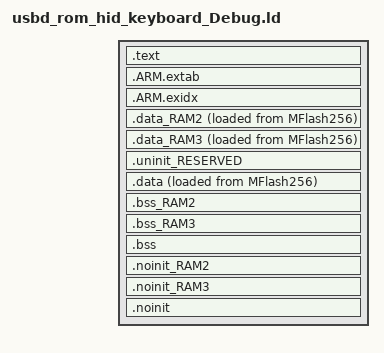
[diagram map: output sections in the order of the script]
/*
 * GENERATED FILE - DO NOT EDIT
 * Copyright 2008-2013 Code Red Technologies Ltd,
 * Copyright 2013-2025 NXP
 * SPDX-License-Identifier: BSD-3-Clause
 * Generated linker script file for LPC1549
 * Created from linkscript.ldt by FMCreateLinkLibraries
 * Using Freemarker v2.3.30
 * MCUXpresso IDE v25.6 [Build 136] [2025-06-27] on 17. 11. 2025 21:48:40
 */

INCLUDE "usbd_rom_hid_keyboard_Debug_library.ld"
INCLUDE "usbd_rom_hid_keyboard_Debug_memory.ld"

ENTRY(ResetISR)

SECTIONS
{
     /* MAIN TEXT SECTION */
    .text : ALIGN(4)
    {
        FILL(0xff)
        __vectors_start__ = ABSOLUTE(.) ;
        KEEP(*(.isr_vector))
        /* Global Section Table */
        . = ALIGN(4) ;
        __section_table_start = .;
        __data_section_table = .;
        LONG(LOADADDR(.data));
        LONG(    ADDR(.data));
        LONG(  SIZEOF(.data));
        LONG(LOADADDR(.data_RAM2));
        LONG(    ADDR(.data_RAM2));
        LONG(  SIZEOF(.data_RAM2));
        LONG(LOADADDR(.data_RAM3));
        LONG(    ADDR(.data_RAM3));
        LONG(  SIZEOF(.data_RAM3));
        __data_section_table_end = .;
        __bss_section_table = .;
        LONG(    ADDR(.bss));
        LONG(  SIZEOF(.bss));
        LONG(    ADDR(.bss_RAM2));
        LONG(  SIZEOF(.bss_RAM2));
        LONG(    ADDR(.bss_RAM3));
        LONG(  SIZEOF(.bss_RAM3));
        __bss_section_table_end = .;
        __section_table_end = . ;
        /* End of Global Section Table */

        *(.after_vectors*)

       *(.text*)
       *(.rodata .rodata.* .constdata .constdata.*)
       . = ALIGN(4);
    } > MFlash256
    /*
     * for exception handling/unwind - some Newlib functions (in common
     * with C++ and STDC++) use this.
     */
    .ARM.extab : ALIGN(4)
    {
        *(.ARM.extab* .gnu.linkonce.armextab.*)
    } > MFlash256

    .ARM.exidx : ALIGN(4)
    {
        __exidx_start = .;
        *(.ARM.exidx* .gnu.linkonce.armexidx.*)
        __exidx_end = .;
    } > MFlash256
 
    _etext = .;
        
    /* DATA section for Ram1_16 */

    .data_RAM2 : ALIGN(4)
    {
        FILL(0xff)
        PROVIDE(__start_data_RAM2 = .) ;
        PROVIDE(__start_data_Ram1_16 = .) ;
        *(.ramfunc.$RAM2)
        *(.ramfunc.$Ram1_16)
        *(.data.$RAM2)
        *(.data.$Ram1_16)
        *(.data.$RAM2.*)
        *(.data.$Ram1_16.*)
        . = ALIGN(4) ;
        PROVIDE(__end_data_RAM2 = .) ;
        PROVIDE(__end_data_Ram1_16 = .) ;
     } > Ram1_16 AT>MFlash256

    /* DATA section for Ram2_4 */

    .data_RAM3 : ALIGN(4)
    {
        FILL(0xff)
        PROVIDE(__start_data_RAM3 = .) ;
        PROVIDE(__start_data_Ram2_4 = .) ;
        *(.ramfunc.$RAM3)
        *(.ramfunc.$Ram2_4)
        *(.data.$RAM3)
        *(.data.$Ram2_4)
        *(.data.$RAM3.*)
        *(.data.$Ram2_4.*)
        . = ALIGN(4) ;
        PROVIDE(__end_data_RAM3 = .) ;
        PROVIDE(__end_data_Ram2_4 = .) ;
     } > Ram2_4 AT>MFlash256

    /* MAIN DATA SECTION */
    .uninit_RESERVED (NOLOAD) : ALIGN(4)
    {
        _start_uninit_RESERVED = .;
        KEEP(*(.bss.$RESERVED*))
       . = ALIGN(4) ;
        _end_uninit_RESERVED = .;
    } > Ram0_16 AT> Ram0_16

    /* Main DATA section (Ram0_16) */
    .data : ALIGN(4)
    {
       FILL(0xff)
       _data = . ;
       PROVIDE(__start_data_RAM = .) ;
       PROVIDE(__start_data_Ram0_16 = .) ;
       *(vtable)
       *(.ramfunc*)
       KEEP(*(CodeQuickAccess))
       KEEP(*(DataQuickAccess))
       *(RamFunction)
       *(.data*)
       . = ALIGN(4) ;
       _edata = . ;
       PROVIDE(__end_data_RAM = .) ;
       PROVIDE(__end_data_Ram0_16 = .) ;
    } > Ram0_16 AT>MFlash256

    /* BSS section for Ram1_16 */
    .bss_RAM2 (NOLOAD) : ALIGN(4)
    {
       PROVIDE(__start_bss_RAM2 = .) ;
       PROVIDE(__start_bss_Ram1_16 = .) ;
       *(.bss.$RAM2)
       *(.bss.$Ram1_16)
       *(.bss.$RAM2.*)
       *(.bss.$Ram1_16.*)
       . = ALIGN (. != 0 ? 4 : 1) ; /* avoid empty segment */
       PROVIDE(__end_bss_RAM2 = .) ;
       PROVIDE(__end_bss_Ram1_16 = .) ;
    } > Ram1_16 AT> Ram1_16

    /* BSS section for Ram2_4 */
    .bss_RAM3 (NOLOAD) : ALIGN(4)
    {
       PROVIDE(__start_bss_RAM3 = .) ;
       PROVIDE(__start_bss_Ram2_4 = .) ;
       *(.bss.$RAM3)
       *(.bss.$Ram2_4)
       *(.bss.$RAM3.*)
       *(.bss.$Ram2_4.*)
       . = ALIGN (. != 0 ? 4 : 1) ; /* avoid empty segment */
       PROVIDE(__end_bss_RAM3 = .) ;
       PROVIDE(__end_bss_Ram2_4 = .) ;
    } > Ram2_4 AT> Ram2_4

    /* MAIN BSS SECTION */
    .bss (NOLOAD) : ALIGN(4)
    {
        _bss = .;
        PROVIDE(__start_bss_RAM = .) ;
        PROVIDE(__start_bss_Ram0_16 = .) ;
        *(.bss*)
        *(COMMON)
        . = ALIGN(4) ;
        _ebss = .;
        PROVIDE(__end_bss_RAM = .) ;
        PROVIDE(__end_bss_Ram0_16 = .) ;
        PROVIDE(end = .);
    } > Ram0_16 AT> Ram0_16

    /* NOINIT section for Ram1_16 */
    .noinit_RAM2 (NOLOAD) : ALIGN(4)
    {
       PROVIDE(__start_noinit_RAM2 = .) ;
       PROVIDE(__start_noinit_Ram1_16 = .) ;
       *(.noinit.$RAM2)
       *(.noinit.$Ram1_16)
       *(.noinit.$RAM2.*)
       *(.noinit.$Ram1_16.*)
       . = ALIGN(4) ;
       PROVIDE(__end_noinit_RAM2 = .) ;
       PROVIDE(__end_noinit_Ram1_16 = .) ;
    } > Ram1_16 AT> Ram1_16

    /* NOINIT section for Ram2_4 */
    .noinit_RAM3 (NOLOAD) : ALIGN(4)
    {
       PROVIDE(__start_noinit_RAM3 = .) ;
       PROVIDE(__start_noinit_Ram2_4 = .) ;
       *(.noinit.$RAM3)
       *(.noinit.$Ram2_4)
       *(.noinit.$RAM3.*)
       *(.noinit.$Ram2_4.*)
       . = ALIGN(4) ;
       PROVIDE(__end_noinit_RAM3 = .) ;
       PROVIDE(__end_noinit_Ram2_4 = .) ;
    } > Ram2_4 AT> Ram2_4

    /* DEFAULT NOINIT SECTION */
    .noinit (NOLOAD): ALIGN(4)
    {
        _noinit = .;
        PROVIDE(__start_noinit_RAM = .) ;
        PROVIDE(__start_noinit_Ram0_16 = .) ;
        *(.noinit*)
         . = ALIGN(4) ;
        _end_noinit = .;
       PROVIDE(__end_noinit_RAM = .) ;
       PROVIDE(__end_noinit_Ram0_16 = .) ;        
    } > Ram0_16 AT> Ram0_16

    PROVIDE(_pvHeapStart = DEFINED(__user_heap_base) ? __user_heap_base : .);

    PROVIDE(_vStackTop = DEFINED(__user_stack_top) ? __user_stack_top : __top_Ram0_16 - 0);

    /* ## Create checksum value (used in startup) ## */
    PROVIDE(__valid_user_code_checksum = 0 - 
                                         (_vStackTop 
                                         + (ResetISR + 1) 
                                         + (NMI_Handler + 1) 
                                         + (HardFault_Handler + 1) 
                                         + (( DEFINED(MemManage_Handler) ? MemManage_Handler : 0 ) + 1)   /* MemManage_Handler may not be defined */
                                         + (( DEFINED(BusFault_Handler) ? BusFault_Handler : 0 ) + 1)     /* BusFault_Handler may not be defined */
                                         + (( DEFINED(UsageFault_Handler) ? UsageFault_Handler : 0 ) + 1) /* UsageFault_Handler may not be defined */
                                         ) );

    /* Provide basic symbols giving location and size of main text
     * block, including initial values of RW data sections. Note that
     * these will need extending to give a complete picture with
     * complex images (e.g multiple Flash banks).
     */
    _image_start = LOADADDR(.text);
    _image_end = LOADADDR(.data) + SIZEOF(.data);
    _image_size = _image_end - _image_start;
}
